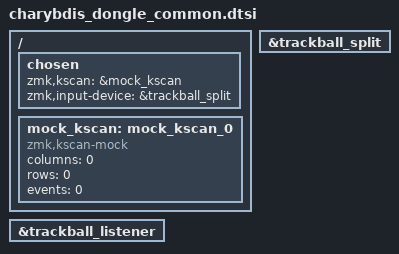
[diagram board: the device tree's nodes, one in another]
#include "charybdis.dtsi"
#include "charybdis_pmw3610.dtsi"
#include "charybdis_pointer.dtsi"

/ {
    chosen {
        zmk,kscan = &mock_kscan;
        zmk,input-device = &trackball_split;
    };

    mock_kscan: mock_kscan_0 {
        compatible = "zmk,kscan-mock";
        columns = <0>;
        rows = <0>;
        events = <0>;
    };
};

&trackball_split {
    status = "okay";
};

&trackball_listener {
    status = "okay";
};
